AUTOSAR XML (schema 4-3-0)
package /App_Model
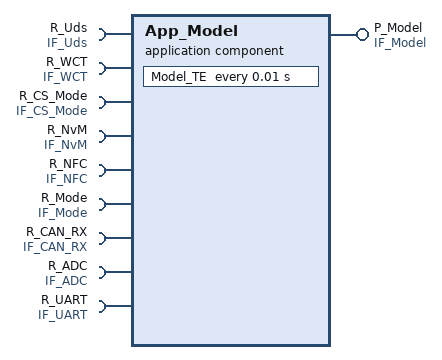
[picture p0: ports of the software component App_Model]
  application sw component type App_Model  # WPC Application Main Component
    6 x require port:
      R_Uds: nonqueued-receiver-com-spec=Uds_STR, required-interface=IF_Uds
      R_WCT: nonqueued-receiver-com-spec=WCT_STR, required-interface=IF_WCT  # None
      R_CS_Mode: required-com-specs=[ModeInit, NvMInit, ApplicationInit], required-interface=IF_CS_Mode  # None
      R_NvM: nonqueued-receiver-com-spec=NvM_STR, required-interface=IF_NvM  # None
      R_NFC: nonqueued-receiver-com-spec=NFC_STR, required-interface=IF_NFC
      R_Mode: nonqueued-receiver-com-spec=Mode_STR, required-interface=IF_Mode
    provide port P_Model: nonqueued-sender-com-spec=Model_STR, provided-interface=IF_Model
    require port R_CAN_RX: nonqueued-receiver-com-spec=CAN_RX_STR, required-interface=IF_CAN_RX
    require port R_ADC: nonqueued-receiver-com-spec=ADC_STR, required-interface=IF_ADC
    require port R_UART: nonqueued-receiver-com-spec=UART_STR, required-interface=IF_UART
    behavior IB_WPC: data-type-mapping=DataTypeMappingSet_WPC, handle-termination-and-restart=NO-SUPPORT  # WPC App IB
      timing event TE_Model_TE: start-on-event=Model_TE, period=0.01
      runnable Model_TE: symbol=Model_TE_Runnable
        data-receive-point-by-arguments:
          8 x access, all with scope=COMMUNICATION-INTER-ECU:
            DRPBA_Model_TE_R_Mode_Structure: accessed-variable=R_Mode.Mode_STR
            DRPBA_Model_TE_R_NvM_Structure: accessed-variable=R_NvM.NvM_STR
            DRPBA_Model_TE_R_ADC_STR: accessed-variable=R_ADC.ADC_STR
            DRPBA_Model_TE_R_BCAN_RX_STR: accessed-variable=R_CAN_RX.CAN_RX_STR
            DRPBA_Model_TE_R_UART_STR: accessed-variable=R_UART.UART_STR
            DRPBA_Model_TE_R_NFC_NFC2_STR: accessed-variable=R_NFC.NFC_STR
            DRPBA_Model_TE_R_WCT_WCT_STR_ALL: accessed-variable=R_WCT.WCT_STR
            DRPBA_Model_TE_R_Uds_Uds_STR: accessed-variable=R_Uds.Uds_STR
        data-send-points:
          access DSP_Model_TE_P_Model_Structure: accessed-variable=P_Model.Model_STR, scope=COMMUNICATION-INTER-ECU
        sync call SSCP_R_CS_Mode_ModeInit: operation=R_CS_Mode.ModeInit, timeout=0.0
        sync call SSCP_R_CS_Mode_NvMInit: operation=R_CS_Mode.NvMInit, timeout=0.0
        sync call SSCP_R_CS_Mode_ApplicationInit: operation=R_CS_Mode.ApplicationInit, timeout=0.0
  sender receiver interface IF_Model  # WPC SWC Output
    data Model_STR: type=IDT_Model_STR
